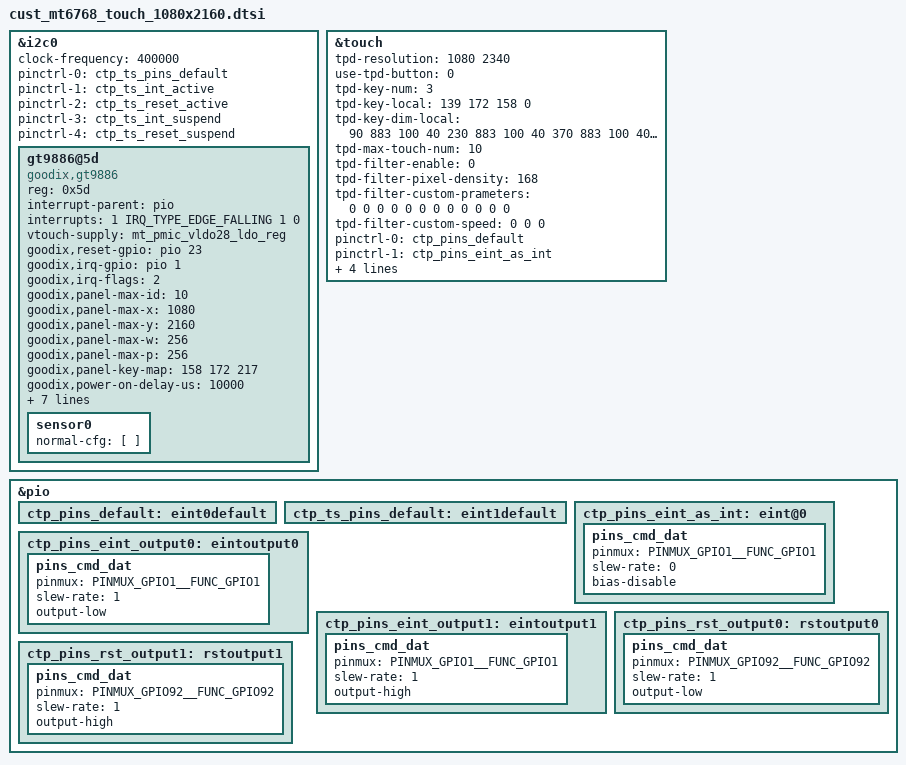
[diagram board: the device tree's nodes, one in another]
// SPDX-License-Identifier: GPL-2.0+
/*
 * Copyright (c) 2019 MediaTek Inc.
 *
 */

/* TOUCH start */
&i2c0 {
	clock-frequency = <400000>;
	pinctrl-names = "default",
		"ts_int_active","ts_reset_active",
		"ts_int_suspend","ts_reset_suspend";
	pinctrl-0 = <&ctp_ts_pins_default>;
	pinctrl-1 = <&ctp_ts_int_active>;
	pinctrl-2 = <&ctp_ts_reset_active>;
	pinctrl-3 = <&ctp_ts_int_suspend>;
	pinctrl-4 = <&ctp_ts_reset_suspend>;
	status = "okay";

	gt9886@5d {
		compatible = "goodix,gt9886";
		reg = <0x5d>;
		status = "ok";
		interrupt-parent = <&pio>;
		interrupts = <1 IRQ_TYPE_EDGE_FALLING 1 0>;
		vtouch-supply = <&mt_pmic_vldo28_ldo_reg>;
		goodix,reset-gpio = <&pio 23 0x0>;
		goodix,irq-gpio = <&pio 1 0x0>;
		goodix,irq-flags = <2>; /* 1:rising, 2:falling;*/
		goodix,panel-max-id = <10>;
		goodix,panel-max-x = <1080>;
		goodix,panel-max-y = <2160>;
		goodix,panel-max-w = <256>;
		goodix,panel-max-p = <256>;
		goodix,panel-key-map = <158 172 217>; /*BACK,HOMEPAGE,SEARCH*/
		goodix,power-on-delay-us = <10000>; /*10ms*/
		goodix,power-off-delay-us = <5000>;
		/*goodix,swap-axis;*/
		goodix,firmware-version = "6785ae";
		goodix,config-version = "6785v99";
		goodix,x2x;
		goodix,y2y;
		goodix,pen-enable;
		goodix,key-of-pen = <331 332>;/*BTN_STYLUS, BTN_STYLUS2*/
		sensor0 {
			normal-cfg = [
			];
		};
	};

};
&touch {
	tpd-resolution = <1080 2340>;
	use-tpd-button = <0>;
	tpd-key-num = <3>;
	tpd-key-local= <139 172 158 0>;
	tpd-key-dim-local = <90 883 100 40 230
				883 100 40 370 883 100 40 0 0 0 0>;
	tpd-max-touch-num = <10>;
	tpd-filter-enable = <0>;
	tpd-filter-pixel-density = <168>;
	tpd-filter-custom-prameters = <0 0 0 0 0 0 0 0 0 0 0 0>;
	tpd-filter-custom-speed = <0 0 0>;
	pinctrl-names = "default", "state_eint_as_int",
		"state_eint_output0", "state_eint_output1",
		"state_rst_output0", "state_rst_output1";
	pinctrl-0 = <&ctp_pins_default>;
	pinctrl-1 = <&ctp_pins_eint_as_int>;
	pinctrl-2 = <&ctp_pins_eint_output0>;
	pinctrl-3 = <&ctp_pins_eint_output1>;
	pinctrl-4 = <&ctp_pins_rst_output0>;
	pinctrl-5 = <&ctp_pins_rst_output1>;
	status = "okay";
};
&pio {
	ctp_pins_default: eint0default {
	};
	ctp_ts_pins_default: eint1default {
	};
	ctp_pins_eint_as_int: eint@0 {
		pins_cmd_dat {
			pinmux = <PINMUX_GPIO1__FUNC_GPIO1>;
			slew-rate = <0>;
			bias-disable;
		};
	};
	ctp_pins_eint_output0: eintoutput0 {
		pins_cmd_dat {
			pinmux = <PINMUX_GPIO1__FUNC_GPIO1>;
			slew-rate = <1>;
			output-low;
		};
	};
	ctp_pins_eint_output1: eintoutput1 {
		pins_cmd_dat {
			pinmux = <PINMUX_GPIO1__FUNC_GPIO1>;
			slew-rate = <1>;
			output-high;
	};
	};
        ctp_pins_rst_output0: rstoutput0 {
               pins_cmd_dat {
                       pinmux = <PINMUX_GPIO92__FUNC_GPIO92>;
                       slew-rate = <1>;
                       output-low;
               };
       };
       ctp_pins_rst_output1: rstoutput1 {
               pins_cmd_dat {
                       pinmux = <PINMUX_GPIO92__FUNC_GPIO92>;
                       slew-rate = <1>;
                       output-high;
               };
       };

};
/* TOUCH end */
